AUTOSAR XML (schema 00046)
package /ComponentTypes
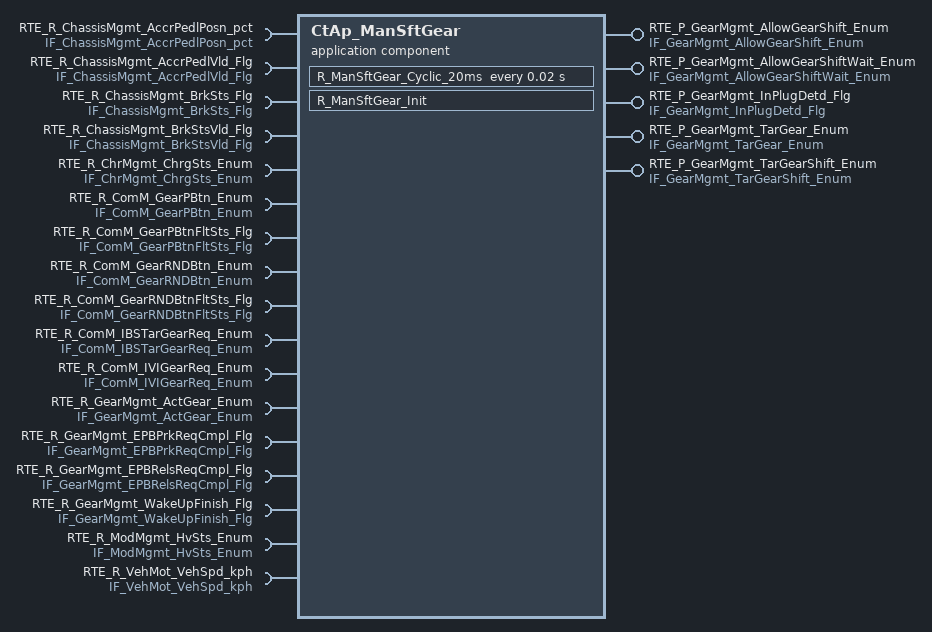
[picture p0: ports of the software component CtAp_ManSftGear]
  application sw component type CtAp_ManSftGear
    5 x provide port:
      RTE_P_GearMgmt_AllowGearShift_Enum: nonqueued-sender-com-spec=tec_GearMgmt_AllowGearShift_Enum, provided-interface=IF_GearMgmt_AllowGearShift_Enum
      RTE_P_GearMgmt_AllowGearShiftWait_Enum: nonqueued-sender-com-spec=tec_GearMgmt_AllowGearShiftWait_Enum, provided-interface=IF_GearMgmt_AllowGearShiftWait_Enum
      RTE_P_GearMgmt_InPlugDetd_Flg: nonqueued-sender-com-spec=tec_GearMgmt_InPlugDetd_Flg, provided-interface=IF_GearMgmt_InPlugDetd_Flg
      RTE_P_GearMgmt_TarGear_Enum: nonqueued-sender-com-spec=tec_GearMgmt_TarGear_Enum, provided-interface=IF_GearMgmt_TarGear_Enum
      RTE_P_GearMgmt_TarGearShift_Enum: nonqueued-sender-com-spec=tec_GearMgmt_TarGearShift_Enum, provided-interface=IF_GearMgmt_TarGearShift_Enum
    17 x require port:
      RTE_R_ChassisMgmt_AccrPedlPosn_pct: nonqueued-receiver-com-spec{data-element=tec_ChassisMgmt_AccrPedlPosn_pct, filter=data-filter-type=ALWAYS}, required-interface=IF_ChassisMgmt_AccrPedlPosn_pct
      RTE_R_ChassisMgmt_AccrPedlVld_Flg: nonqueued-receiver-com-spec{data-element=tec_ChassisMgmt_AccrPedlVld_Flg, filter=data-filter-type=ALWAYS}, required-interface=IF_ChassisMgmt_AccrPedlVld_Flg
      RTE_R_ChassisMgmt_BrkSts_Flg: nonqueued-receiver-com-spec{data-element=tec_ChassisMgmt_BrkSts_Flg, filter=data-filter-type=ALWAYS}, required-interface=IF_ChassisMgmt_BrkSts_Flg
      RTE_R_ChassisMgmt_BrkStsVld_Flg: nonqueued-receiver-com-spec{data-element=tec_ChassisMgmt_BrkStsVld_Flg, filter=data-filter-type=ALWAYS}, required-interface=IF_ChassisMgmt_BrkStsVld_Flg
      RTE_R_ChrMgmt_ChrgSts_Enum: nonqueued-receiver-com-spec{data-element=tec_ChrMgmt_ChrgSts_Enum, filter=data-filter-type=ALWAYS}, required-interface=IF_ChrMgmt_ChrgSts_Enum
      RTE_R_ComM_GearPBtn_Enum: nonqueued-receiver-com-spec{data-element=tec_ComM_GearPBtn_Enum, filter=data-filter-type=ALWAYS}, required-interface=IF_ComM_GearPBtn_Enum
      RTE_R_ComM_GearPBtnFltSts_Flg: nonqueued-receiver-com-spec{data-element=tec_ComM_GearPBtnFltSts_Flg, filter=data-filter-type=ALWAYS}, required-interface=IF_ComM_GearPBtnFltSts_Flg
      RTE_R_ComM_GearRNDBtn_Enum: nonqueued-receiver-com-spec{data-element=tec_ComM_GearRNDBtn_Enum, filter=data-filter-type=ALWAYS}, required-interface=IF_ComM_GearRNDBtn_Enum
      RTE_R_ComM_GearRNDBtnFltSts_Flg: nonqueued-receiver-com-spec{data-element=tec_ComM_GearRNDBtnFltSts_Flg, filter=data-filter-type=ALWAYS}, required-interface=IF_ComM_GearRNDBtnFltSts_Flg
      RTE_R_ComM_IBSTarGearReq_Enum: nonqueued-receiver-com-spec{data-element=tec_ComM_IBSTarGearReq_Enum, filter=data-filter-type=ALWAYS}, required-interface=IF_ComM_IBSTarGearReq_Enum
      RTE_R_ComM_IVIGearReq_Enum: nonqueued-receiver-com-spec{data-element=tec_ComM_IVIGearReq_Enum, filter=data-filter-type=ALWAYS}, required-interface=IF_ComM_IVIGearReq_Enum
      RTE_R_GearMgmt_ActGear_Enum: nonqueued-receiver-com-spec{data-element=tec_GearMgmt_ActGear_Enum, filter=data-filter-type=ALWAYS}, required-interface=IF_GearMgmt_ActGear_Enum
      RTE_R_GearMgmt_EPBPrkReqCmpl_Flg: nonqueued-receiver-com-spec{data-element=tec_GearMgmt_EPBPrkReqCmpl_Flg, filter=data-filter-type=ALWAYS}, required-interface=IF_GearMgmt_EPBPrkReqCmpl_Flg
      RTE_R_GearMgmt_EPBRelsReqCmpl_Flg: nonqueued-receiver-com-spec{data-element=tec_GearMgmt_EPBRelsReqCmpl_Flg, filter=data-filter-type=ALWAYS}, required-interface=IF_GearMgmt_EPBRelsReqCmpl_Flg
      RTE_R_GearMgmt_WakeUpFinish_Flg: nonqueued-receiver-com-spec{data-element=tec_GearMgmt_WakeUpFinish_Flg, filter=data-filter-type=ALWAYS}, required-interface=IF_GearMgmt_WakeUpFinish_Flg
      RTE_R_ModMgmt_HvSts_Enum: nonqueued-receiver-com-spec{data-element=tec_ModMgmt_HvSts_Enum, filter=data-filter-type=ALWAYS}, required-interface=IF_ModMgmt_HvSts_Enum
      RTE_R_VehMot_VehSpd_kph: nonqueued-receiver-com-spec{data-element=tec_VehMot_VehSpd_kph, filter=data-filter-type=ALWAYS}, required-interface=IF_VehMot_VehSpd_kph
    behavior CtAp_ManSftGear_InternalBehavior
      timing event TMT_R_ManSftGear_Cyclic_20ms: start-on-event=R_ManSftGear_Cyclic_20ms, period=0.02
      init event CtAp_ManSftGear_InitEvent: start-on-event=R_ManSftGear_Init
      runnable R_ManSftGear_Cyclic_20ms
        data-receive-point-by-arguments:
          17 x access:
            REC_RTE_R_ChassisMgmt_AccrPedlPosn_pct_tec_ChassisMgmt_AccrPedlPosn_pct: accessed-variable=RTE_R_ChassisMgmt_AccrPedlPosn_pct.tec_ChassisMgmt_AccrPedlPosn_pct
            REC_RTE_R_ChassisMgmt_AccrPedlVld_Flg_tec_ChassisMgmt_AccrPedlVld_Flg: accessed-variable=RTE_R_ChassisMgmt_AccrPedlVld_Flg.tec_ChassisMgmt_AccrPedlVld_Flg
            REC_RTE_R_ChassisMgmt_BrkSts_Flg_tec_ChassisMgmt_BrkSts_Flg: accessed-variable=RTE_R_ChassisMgmt_BrkSts_Flg.tec_ChassisMgmt_BrkSts_Flg
            REC_RTE_R_ChassisMgmt_BrkStsVld_Flg_tec_ChassisMgmt_BrkStsVld_Flg: accessed-variable=RTE_R_ChassisMgmt_BrkStsVld_Flg.tec_ChassisMgmt_BrkStsVld_Flg
            REC_RTE_R_ChrMgmt_ChrgSts_Enum_tec_ChrMgmt_ChrgSts_Enum: accessed-variable=RTE_R_ChrMgmt_ChrgSts_Enum.tec_ChrMgmt_ChrgSts_Enum
            REC_RTE_R_ComM_GearPBtn_Enum_tec_ComM_GearPBtn_Enum: accessed-variable=RTE_R_ComM_GearPBtn_Enum.tec_ComM_GearPBtn_Enum
            REC_RTE_R_ComM_GearPBtnFltSts_Flg_tec_ComM_GearPBtnFltSts_Flg: accessed-variable=RTE_R_ComM_GearPBtnFltSts_Flg.tec_ComM_GearPBtnFltSts_Flg
            REC_RTE_R_ComM_GearRNDBtn_Enum_tec_ComM_GearRNDBtn_Enum: accessed-variable=RTE_R_ComM_GearRNDBtn_Enum.tec_ComM_GearRNDBtn_Enum
            REC_RTE_R_ComM_GearRNDBtnFltSts_Flg_tec_ComM_GearRNDBtnFltSts_Flg: accessed-variable=RTE_R_ComM_GearRNDBtnFltSts_Flg.tec_ComM_GearRNDBtnFltSts_Flg
            REC_RTE_R_ComM_IBSTarGearReq_Enum_tec_ComM_IBSTarGearReq_Enum: accessed-variable=RTE_R_ComM_IBSTarGearReq_Enum.tec_ComM_IBSTarGearReq_Enum
            REC_RTE_R_ComM_IVIGearReq_Enum_tec_ComM_IVIGearReq_Enum: accessed-variable=RTE_R_ComM_IVIGearReq_Enum.tec_ComM_IVIGearReq_Enum
            REC_RTE_R_GearMgmt_ActGear_Enum_tec_GearMgmt_ActGear_Enum: accessed-variable=RTE_R_GearMgmt_ActGear_Enum.tec_GearMgmt_ActGear_Enum
            REC_RTE_R_GearMgmt_EPBPrkReqCmpl_Flg_tec_GearMgmt_EPBPrkReqCmpl_Flg: accessed-variable=RTE_R_GearMgmt_EPBPrkReqCmpl_Flg.tec_GearMgmt_EPBPrkReqCmpl_Flg
            REC_RTE_R_GearMgmt_EPBRelsReqCmpl_Flg_tec_GearMgmt_EPBRelsReqCmpl_Flg: accessed-variable=RTE_R_GearMgmt_EPBRelsReqCmpl_Flg.tec_GearMgmt_EPBRelsReqCmpl_Flg
            REC_RTE_R_GearMgmt_WakeUpFinish_Flg_tec_GearMgmt_WakeUpFinish_Flg: accessed-variable=RTE_R_GearMgmt_WakeUpFinish_Flg.tec_GearMgmt_WakeUpFinish_Flg
            REC_RTE_R_ModMgmt_HvSts_Enum_tec_ModMgmt_HvSts_Enum: accessed-variable=RTE_R_ModMgmt_HvSts_Enum.tec_ModMgmt_HvSts_Enum
            REC_RTE_R_VehMot_VehSpd_kph_tec_VehMot_VehSpd_kph: accessed-variable=RTE_R_VehMot_VehSpd_kph.tec_VehMot_VehSpd_kph
        data-send-points:
          5 x access:
            SEND_RTE_P_GearMgmt_AllowGearShift_Enum_tec_GearMgmt_AllowGearShift_Enum: accessed-variable=RTE_P_GearMgmt_AllowGearShift_Enum.tec_GearMgmt_AllowGearShift_Enum
            SEND_RTE_P_GearMgmt_AllowGearShiftWait_Enum_tec_GearMgmt_AllowGearShiftWait_Enum: accessed-variable=RTE_P_GearMgmt_AllowGearShiftWait_Enum.tec_GearMgmt_AllowGearShiftWait_Enum
            SEND_RTE_P_GearMgmt_InPlugDetd_Flg_tec_GearMgmt_InPlugDetd_Flg: accessed-variable=RTE_P_GearMgmt_InPlugDetd_Flg.tec_GearMgmt_InPlugDetd_Flg
            SEND_RTE_P_GearMgmt_TarGear_Enum_tec_GearMgmt_TarGear_Enum: accessed-variable=RTE_P_GearMgmt_TarGear_Enum.tec_GearMgmt_TarGear_Enum
            SEND_RTE_P_GearMgmt_TarGearShift_Enum_tec_GearMgmt_TarGearShift_Enum: accessed-variable=RTE_P_GearMgmt_TarGearShift_Enum.tec_GearMgmt_TarGearShift_Enum
      runnable R_ManSftGear_Init
  swc implementation CtAp_ManSftGear_Implementation: behavior=CtAp_ManSftGear_InternalBehavior
    code-descriptors:
      code Default: artifact-descriptors=autosar-engineering-object={short-label=Default, category=SWOBJ}
